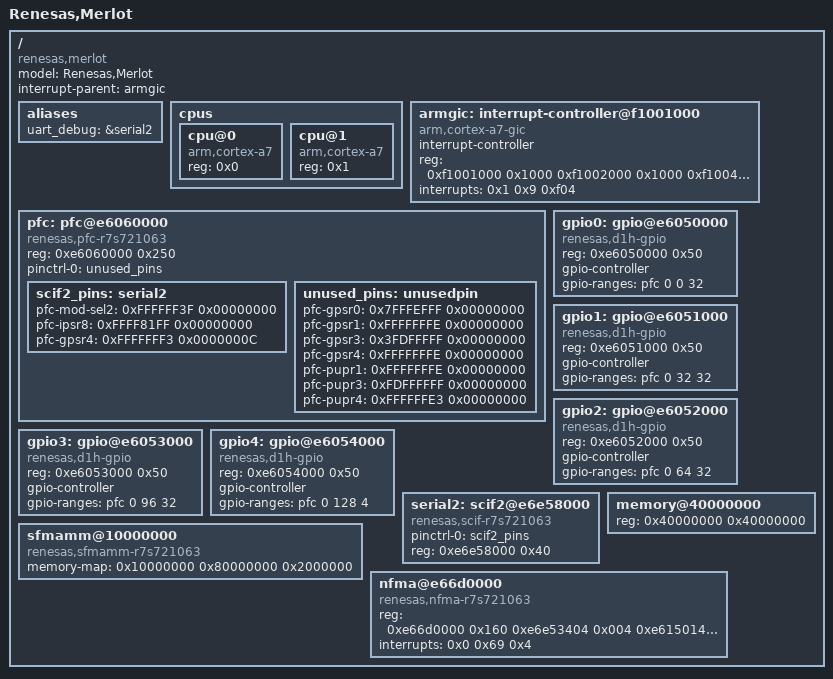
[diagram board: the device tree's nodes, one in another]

/dts-v1/;

/ {
    /* This DTS is made for the Renesas Merlot board */
    compatible = "renesas,merlot", "renesas,r7s721063";
    model = "Renesas,Merlot";
    interrupt-parent = <&armgic>;
    
   /* 
        The default encoding for all peripheral register banks:
        64Bit base address
        64Bit bank size
    */
    #address-cells = <0x1>;
    #size-cells = <0x1>;

    aliases {
		uart_debug = &serial2;
	};

    cpus {
        /* 
           For CPU sub-notes the 'reg' property represents the number of the
           CPU core. The number is encoded as 32bit value in the address field
        */
        #address-cells = <0x1>;
        #size-cells = <0x0>;

        cpu@0 {
            device_type = "cpu";
            compatible = "arm,cortex-a7";
            reg = <0x0>;
            /* Clock frequencies are set by boot loader/init script */
            /* clock-frequency = <0x0>; */
        };

        cpu@1 {
            device_type = "cpu";
            compatible = "arm,cortex-a7";
            reg = <0x1>;
            /* Clock frequencies are set by boot loader/init script */
            /* clock-frequency = <0x0>; */
        };
    };

    armgic: interrupt-controller@f1001000 {
        compatible = "arm,cortex-a7-gic";
        #interrupt-cells = <0x3>;

        interrupt-controller;
        reg = <0xf1001000 0x1000
               0xf1002000 0x1000
               0xf1004000 0x2000
               0xf1006000 0x2000>;

        /*  Interrupt signal is defined as following
            IRQ_LEVEL        = (1 <<  8),
            IRQ_PER_CPU      = (1 <<  9),
            IRQ_NOPROBE      = (1 << 10),
            IRQ_NOREQUEST    = (1 << 11),
            
            IRQ_TYPE_LEVEL_HIGH = 0x4
        */

        /* interrupt-type (PPI), interrupt number, interrupt signal */
        interrupts = <0x1 0x9 0xf04>;
    };
    pfc: pfc@e6060000 {
        compatible = "renesas,pfc-r7s721063","d1h,pfc";
        reg = <0xe6060000 0x250>;
        status = "okay";
        /* Use pin configuration 0 */
        /* Alternative configurations e.g. pinctrl-1 are currently not supported */
        pinctrl-names = "default";
        pinctrl-0= <&unused_pins>;
    };

    gpio0: gpio@e6050000 {
        compatible = "renesas,d1h-gpio";
        reg = <0xe6050000 0x50>;
        gpio-controller;
        gpio-ranges = <&pfc 0 0 32>;
	};

    gpio1: gpio@e6051000 {
        compatible = "renesas,d1h-gpio";
        reg = <0xe6051000 0x50>;
        gpio-controller;
        gpio-ranges = <&pfc 0 32 32>;
	};

    gpio2: gpio@e6052000 {
        compatible = "renesas,d1h-gpio";
        reg = <0xe6052000 0x50>;
        gpio-controller;
        gpio-ranges = <&pfc 0 64 32>;
	};

    gpio3: gpio@e6053000 {
        compatible = "renesas,d1h-gpio";
        reg = <0xe6053000 0x50>;
        gpio-controller;
        gpio-ranges = <&pfc 0 96 32>;
	};

    gpio4: gpio@e6054000 {
        compatible = "renesas,d1h-gpio";
        reg = <0xe6054000 0x50>;
        gpio-controller;
        gpio-ranges = <&pfc 0 128 4>;
	};

    serial2:scif2@e6e58000 {
        compatible = "renesas,scif-r7s721063", "renesas,scif","d1h,serial";
        pinctrl-names = "default";
        pinctrl-0= <&scif2_pins>;
        /* SCIF0 base address */
        reg = <0xe6e58000 0x40>;
        status = "okay";
    };

    memory@40000000 {
        device_type = "memory";
        reg = <0x40000000 0x40000000>; /*1 GB*/
    };

    /* Memory map SFMA (enable by merlot loader) content into to kernel space */ 
    sfmamm@10000000 {
        compatible = "renesas,sfmamm-r7s721063";
       
        /* The 'memory-map' is proprietary naming. We can't use 'reg' because
           Integrity tries to map this into kernel memory. Maybe one could use
          'ranges' properties but it not clear if the OS processes it somehow.
          To be safe we're using a dedicated 'memory-map' property.
          Format is physical address, mapped address (kernel), length, all 32bit
        */
        memory-map = <0x10000000 0x80000000 0x2000000>; /*physical Addr.; mapped Addr; size 0x2000000 ->32MB NOR */

        status = "ok";
    };

    /* NFMA (NAND) */
    nfma@e66d0000 {
        #address-cells = <0x1>;
        #size-cells = <0x0>;
        compatible = "renesas,nfma-r7s721063";

        reg = <0xe66d0000 0x160   /* NFMA base */
               0xe6e53404 0x004   /* NFMAFASTTR */
               0xe6150144 0x004>; /* SMSTPCR5 */
        
        /*  Interrupt signal is defined as following

            IRQ_TYPE_LEVEL_HIGH = 0x4
        */

        /* interrupt-type (SPI), interrupt number, interrupt signal */
        interrupts = <0x0 0x69 0x4>;      /* NFMA interrupt vector */
        status = "ok";
    };  
    
};

&pfc {
    scif2_pins: serial2 {
        /* MOD_SEL[7:6]=2'b00 */
        pfc-mod-sel2= < 0xFFFFFF3F 0x00000000 >;

        /*
            SCIF2_RXD
            IP8[11:9]=3'b000
            SCIF2_TXD
            IP8[14:12]=3'b000
        */
        pfc-ipsr8=< 0xFFFF81FF 0x00000000 >;

        /* GP4[3:2] select function by IP8 */
        pfc-gpsr4=< 0xFFFFFFF3 0x0000000C >;
    };

    unused_pins:unusedpin {
        /*GP0_12 GP3_21 GP3_30 GP3_31 GP4_0 not used,pull up/down disable;GP0_31 nand reset,high pull up, GP1_0 nand wp low pull up disable*/
        pfc-gpsr0=< 0x7FFFEFFF 0x00000000 >;
        pfc-gpsr1=< 0xFFFFFFFE 0x00000000 >;
        pfc-gpsr3=< 0x3FDFFFFF 0x00000000 >;
        pfc-gpsr4=< 0xFFFFFFFE 0x00000000 >;
        pfc-pupr1=< 0xFFFFFFFE 0x00000000 >;
        pfc-pupr3=< 0xFDFFFFFF 0x00000000 >;
        pfc-pupr4=< 0xFFFFFFE3 0x00000000 >;
    };
};
